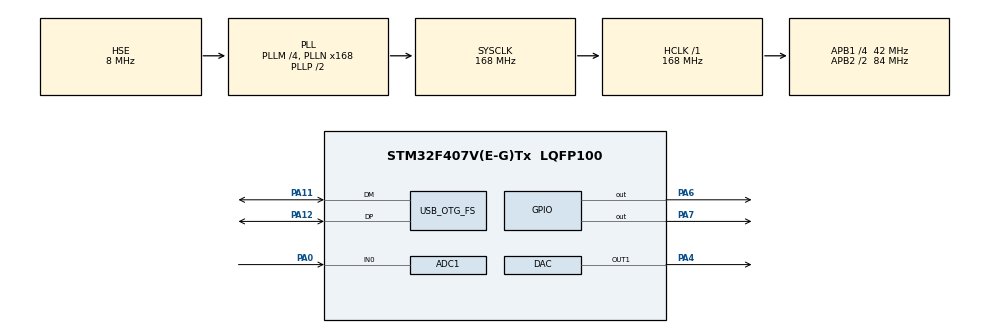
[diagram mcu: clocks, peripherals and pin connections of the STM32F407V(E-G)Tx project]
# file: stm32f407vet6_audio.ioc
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ADC1.Channel-0\#ChannelRegularConversion=ADC_CHANNEL_0
ADC1.ContinuousConvMode=DISABLE
ADC1.DMAContinuousRequests=ENABLE
ADC1.ExternalTrigConv=ADC_EXTERNALTRIGCONV_T3_TRGO
ADC1.ExternalTrigConvEdge=ADC_EXTERNALTRIGCONVEDGE_RISING
ADC1.NbrOfConversionFlag=1
ADC1.Rank-0\#ChannelRegularConversion=1
ADC1.SamplingTime-0\#ChannelRegularConversion=ADC_SAMPLETIME_3CYCLES
ADC1.ScanConvMode=DISABLE
ADC1.master=1
DAC.DAC_Trigger=DAC_TRIGGER_T2_TRGO
Dma.ADC1.0.Direction=DMA_PERIPH_TO_MEMORY
Dma.ADC1.0.FIFOMode=DMA_FIFOMODE_DISABLE
Dma.ADC1.0.Instance=DMA2_Stream0
Dma.ADC1.0.MemDataAlignment=DMA_MDATAALIGN_HALFWORD
Dma.ADC1.0.MemInc=DMA_MINC_ENABLE
Dma.ADC1.0.Mode=DMA_CIRCULAR
Dma.ADC1.0.PeriphDataAlignment=DMA_PDATAALIGN_HALFWORD
Dma.ADC1.0.PeriphInc=DMA_PINC_DISABLE
Dma.ADC1.0.Priority=DMA_PRIORITY_LOW
Dma.DAC1.1.Direction=DMA_MEMORY_TO_PERIPH
Dma.DAC1.1.FIFOMode=DMA_FIFOMODE_DISABLE
Dma.DAC1.1.Instance=DMA1_Stream5
Dma.DAC1.1.MemDataAlignment=DMA_MDATAALIGN_HALFWORD
Dma.DAC1.1.MemInc=DMA_MINC_ENABLE
Dma.DAC1.1.Mode=DMA_NORMAL
Dma.DAC1.1.PeriphDataAlignment=DMA_PDATAALIGN_HALFWORD
Dma.DAC1.1.PeriphInc=DMA_PINC_DISABLE
Dma.DAC1.1.Priority=DMA_PRIORITY_LOW
Dma.Request0=ADC1
Dma.Request1=DAC1
Mcu.Family=STM32F4
Mcu.Name=STM32F407V(E-G)Tx
Mcu.Package=LQFP100
NVIC.DMA1_Stream5_IRQn=true\:0\:0\:false\:false\:true\:false
NVIC.DMA2_Stream0_IRQn=true\:0\:0\:false\:false\:true\:false
NVIC.OTG_FS_IRQn=true\:0\:0\:false\:false\:true\:false
NVIC.PriorityGroup=NVIC_PRIORITYGROUP_4
PA0-WKUP.Signal=ADCx_IN0
PA11.Mode=Device_Only
PA11.Signal=USB_OTG_FS_DM
PA12.Mode=Device_Only
PA12.Signal=USB_OTG_FS_DP
PA13.Mode=Serial_Wire
PA13.Signal=SYS_JTMS-SWDIO
PA14.Mode=Serial_Wire
PA14.Signal=SYS_JTCK-SWCLK
PA4.Signal=COMP_DAC1_group
PA6.Signal=GPIO_Output
PA7.Signal=GPIO_Output
PH0-OSC_IN.Mode=HSE-External-Oscillator
PH0-OSC_IN.Signal=RCC_OSC_IN
PH1-OSC_OUT.Mode=HSE-External-Oscillator
PH1-OSC_OUT.Signal=RCC_OSC_OUT
ProjectManager.HeapSize=0x200
ProjectManager.StackSize=0x400
ProjectManager.TargetToolchain=Makefile
RCC.48MHZClocksFreq_Value=48000000
RCC.AHBFreq_Value=168000000
RCC.APB1CLKDivider=RCC_HCLK_DIV4
RCC.APB1Freq_Value=42000000
RCC.APB1TimFreq_Value=84000000
RCC.APB2CLKDivider=RCC_HCLK_DIV2
RCC.APB2Freq_Value=84000000
RCC.APB2TimFreq_Value=168000000
RCC.CortexFreq_Value=168000000
RCC.HCLKFreq_Value=168000000
RCC.HSE_VALUE=8000000
RCC.HSI_VALUE=16000000
RCC.LSE_VALUE=32768
RCC.PLLM=4
RCC.PLLN=168
RCC.PLLQ=7
RCC.SYSCLKFreq_VALUE=168000000
RCC.SYSCLKSource=RCC_SYSCLKSOURCE_PLLCLK
RCC.VCOOutputFreq_Value=336000000
SH.ADCx_IN0.0=ADC1_IN0,IN0
SH.COMP_DAC1_group.0=DAC_OUT1,DAC_OUT1
TIM2.Period=(84000000 / 128000) -1
TIM2.TIM_MasterOutputTrigger=TIM_TRGO_UPDATE
TIM3.Period=(84000000 / 128000) -1
TIM3.TIM_MasterOutputTrigger=TIM_TRGO_UPDATE
USB_DEVICE.CLASS_NAME_FS=CDC
USB_DEVICE.VirtualMode-CDC_FS=Cdc
USB_DEVICE.VirtualModeFS=Cdc_FS
USB_OTG_FS.VirtualMode=Device_Only
VP_TIM2_VS_ClockSourceINT.Mode=Internal
VP_TIM3_VS_ClockSourceINT.Mode=Internal
VP_USB_DEVICE_VS_USB_DEVICE_CDC_FS.Mode=CDC_FS
board=custom

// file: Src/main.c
/* USER CODE BEGIN Header */
/**
  ******************************************************************************
  * @file           : main.c
  * @brief          : Main program body
  ******************************************************************************
  ** This notice applies to any and all portions of this file
  * that are not between comment pairs USER CODE BEGIN and
  * USER CODE END. Other portions of this file, whether
  * inserted by the user or by software development tools
  * are owned by their respective copyright owners.
  *
  * COPYRIGHT(c) 2019 STMicroelectronics
  *
  * Redistribution and use in source and binary forms, with or without modification,
  * are permitted provided that the following conditions are met:
  *   1. Redistributions of source code must retain the above copyright notice,
  *      this list of conditions and the following disclaimer.
  *   2. Redistributions in binary form must reproduce the above copyright notice,
  *      this list of conditions and the following disclaimer in the documentation
  *      and/or other materials provided with the distribution.
  *   3. Neither the name of STMicroelectronics nor the names of its contributors
  *      may be used to endorse or promote products derived from this software
  *      without specific prior written permission.
  *
  * THIS SOFTWARE IS PROVIDED BY THE COPYRIGHT HOLDERS AND CONTRIBUTORS "AS IS"
  * AND ANY EXPRESS OR IMPLIED WARRANTIES, INCLUDING, BUT NOT LIMITED TO, THE
  * IMPLIED WARRANTIES OF MERCHANTABILITY AND FITNESS FOR A PARTICULAR PURPOSE ARE
  * DISCLAIMED. IN NO EVENT SHALL THE COPYRIGHT HOLDER OR CONTRIBUTORS BE LIABLE
  * FOR ANY DIRECT, INDIRECT, INCIDENTAL, SPECIAL, EXEMPLARY, OR CONSEQUENTIAL
  * DAMAGES (INCLUDING, BUT NOT LIMITED TO, PROCUREMENT OF SUBSTITUTE GOODS OR
  * SERVICES; LOSS OF USE, DATA, OR PROFITS; OR BUSINESS INTERRUPTION) HOWEVER
  * CAUSED AND ON ANY THEORY OF LIABILITY, WHETHER IN CONTRACT, STRICT LIABILITY,
  * OR TORT (INCLUDING NEGLIGENCE OR OTHERWISE) ARISING IN ANY WAY OUT OF THE USE
  * OF THIS SOFTWARE, EVEN IF ADVISED OF THE POSSIBILITY OF SUCH DAMAGE.
  *
  ******************************************************************************
  */
/* USER CODE END Header */

#include "main.h"
#include "adc.h"
#include "dac.h"
#include "dma.h"
#include "tim.h"
#include "usb_device.h"
#include "gpio.h"

/* USER CODE BEGIN Includes */
#include "app.h"

/* USER CODE END Includes */

void SystemClock_Config(void);

int main(void)
{

  /* MCU Configuration--------------------------------------------------------*/

  /* Reset of all peripherals, Initializes the Flash interface and the Systick. */
  HAL_Init();

  /* USER CODE BEGIN Init */
  app_init_f();
  /* USER CODE END Init */

  /* Configure the system clock */
  SystemClock_Config();

  /* Initialize all configured peripherals */
  MX_GPIO_Init();
  MX_DMA_Init();
  MX_ADC1_Init();
  MX_DAC_Init();
  MX_USB_DEVICE_Init();
  MX_TIM2_Init();
  MX_TIM3_Init();
  /* USER CODE BEGIN 2 */
  app_init();
  app_start();
  /* USER CODE END 2 */

  /* Infinite loop */
  while (1)
  {

    /* USER CODE BEGIN 3 */
    app_loop();
  }
  /* USER CODE END 3 */
}

void SystemClock_Config(void)
{
  RCC_OscInitTypeDef RCC_OscInitStruct = {0};
  RCC_ClkInitTypeDef RCC_ClkInitStruct = {0};

  /**Configure the main internal regulator output voltage
  */
  __HAL_RCC_PWR_CLK_ENABLE();
  __HAL_PWR_VOLTAGESCALING_CONFIG(PWR_REGULATOR_VOLTAGE_SCALE1);
  /**Initializes the CPU, AHB and APB busses clocks
  */
  RCC_OscInitStruct.OscillatorType = RCC_OSCILLATORTYPE_HSE;
  RCC_OscInitStruct.HSEState = RCC_HSE_ON;
  RCC_OscInitStruct.PLL.PLLState = RCC_PLL_ON;
  RCC_OscInitStruct.PLL.PLLSource = RCC_PLLSOURCE_HSE;
  RCC_OscInitStruct.PLL.PLLM = 4;
  RCC_OscInitStruct.PLL.PLLN = 168;
  RCC_OscInitStruct.PLL.PLLP = RCC_PLLP_DIV2;
  RCC_OscInitStruct.PLL.PLLQ = 7;
  if (HAL_RCC_OscConfig(&RCC_OscInitStruct) != HAL_OK)
  {
    Error_Handler();
  }
  /**Initializes the CPU, AHB and APB busses clocks
  */
  RCC_ClkInitStruct.ClockType = RCC_CLOCKTYPE_HCLK|RCC_CLOCKTYPE_SYSCLK
                              |RCC_CLOCKTYPE_PCLK1|RCC_CLOCKTYPE_PCLK2;
  RCC_ClkInitStruct.SYSCLKSource = RCC_SYSCLKSOURCE_PLLCLK;
  RCC_ClkInitStruct.AHBCLKDivider = RCC_SYSCLK_DIV1;
  RCC_ClkInitStruct.APB1CLKDivider = RCC_HCLK_DIV4;
  RCC_ClkInitStruct.APB2CLKDivider = RCC_HCLK_DIV2;

  if (HAL_RCC_ClockConfig(&RCC_ClkInitStruct, FLASH_LATENCY_5) != HAL_OK)
  {
    Error_Handler();
  }
}

void Error_Handler(void)
{
}

/************************ (C) COPYRIGHT STMicroelectronics *****END OF FILE****/
